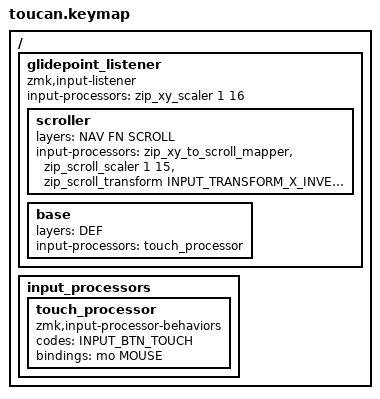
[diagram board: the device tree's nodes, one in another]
#define CONFIG_WIRELESS


// Define to indicate we have a physical mouse/touchpad
#define HAS_MOUSE
#define SCROLL 8

#define ZMK_BASE_LAYER(name, LT, RT, LM, RM, LB, RB, LH, RH)     \
    ZMK_42_LAYER(name, LT, RT, LM, RM, LB, RB, LH, RH, \
        &kp ESC,    &kp TAB , &grave_tilde,    \
        &plus_equal, &kp BSPC, &colon_fslh,        \
        &lt_dash NUM 0, SMART_SYMB               \
    )

#include "zmk_42_layer.h"
#include "zmk-helpers/key-labels/42.h"
#include "base.keymap"
#include "zmk_studio.h"

/ {
    glidepoint_listener: glidepoint_listener {
        compatible = "zmk,input-listener";

        input-processors = <
            &zip_xy_scaler 1 16 // lowering to 0.0625x
            >;
        
        scroller {
            layers = <NAV FN SCROLL>;
            input-processors = <
                &zip_xy_to_scroll_mapper
                &zip_scroll_scaler 1 15
                &zip_scroll_transform INPUT_TRANSFORM_X_INVERT
            >;
        };
        base {
            layers = <DEF>;
            input-processors = <
                &touch_processor    
            >;        
        };        
    };

    // FIXME turn on smooth scrolling
    input_processors {
        touch_processor: touch_processor {
            compatible = "zmk,input-processor-behaviors";
            #input-processor-cells = <0>;
 
            codes = <INPUT_BTN_TOUCH>;      // watch for the 'touch' pseudo button
            bindings  = <&mo MOUSE>;            // Activate Layer 4 while held &mo 4
        };
    };
};
